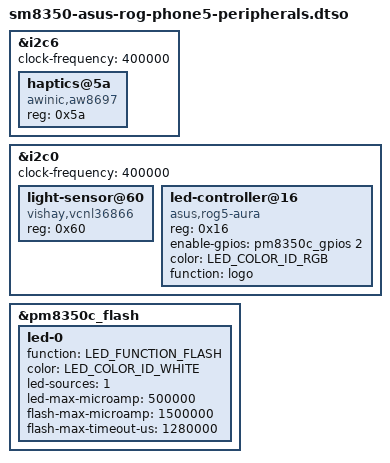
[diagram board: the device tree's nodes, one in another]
// SPDX-License-Identifier: BSD-3-Clause
/*
 * Haptics, the front light/proximity sensor and the back logo LED, all on QUP
 * wrapper 0 next to the touchscreen (stock ZS673KS DT, MP board = PR1/ER2/ER1
 * overrides):
 *   SE6 I2C (i2c@998000): AW8697 LRA driver at 0x5a (chip ID 0x97), VBAT
 *     powered. tools/aw8697 drives it in CONT mode as an input FF device.
 *   SE0 I2C (i2c@980000): VCNL36866 light/proximity at 0x60 (ID 0x62),
 *     tools/vcnl36866 (IIO); and the MS51 Aura MCU at 0x16, powered by
 *     PM8350C GPIO 2 ("logo_5p0_en", hw_stage 5), tools/aura (multicolor
 *     LED rgb:logo).
 * The rear camera flash (torch) is PM8350C flash channel 1 (stock flash_0 /
 * torch_0, qcom,id 0): torch up to 500 mA (stock default 200 mA), flash
 * 1.5 A for at most 1280 ms; leds-qcom-flash exposes it as white:flash.
 * All three I2C devices answered on the r33 default boot with the buses enabled at run
 * time (2026-09-24).
 *
 * The sensor's supply is PM8350C LDO7 ("vcc_psensor"), which the boot chain
 * leaves on. Declaring LDO7 to Linux (3.3 V, HPM) reset the phone within the
 * first second of kernel boot (trial r34); SE6 alone (r35) and SE0 alone
 * without LDO7 (r36) booted, so the regulator stays undeclared.
 */
/dts-v1/;
/plugin/;

#include <dt-bindings/gpio/gpio.h>
#include <dt-bindings/leds/common.h>

&i2c6 {
	clock-frequency = <400000>;
	status = "okay";

	haptics@5a {
		compatible = "awinic,aw8697";
		reg = <0x5a>;
	};
};

&i2c0 {
	clock-frequency = <400000>;
	status = "okay";

	light-sensor@60 {
		compatible = "vishay,vcnl36866";
		reg = <0x60>;
	};

	led-controller@16 {
		compatible = "asus,rog5-aura";
		reg = <0x16>;
		enable-gpios = <&pm8350c_gpios 2 GPIO_ACTIVE_HIGH>;
		color = <LED_COLOR_ID_RGB>;
		function = "logo";
	};
};

&pm8350c_flash {
	status = "okay";

	led-0 {
		function = LED_FUNCTION_FLASH;
		color = <LED_COLOR_ID_WHITE>;
		led-sources = <1>;
		led-max-microamp = <500000>;
		flash-max-microamp = <1500000>;
		flash-max-timeout-us = <1280000>;
	};
};
